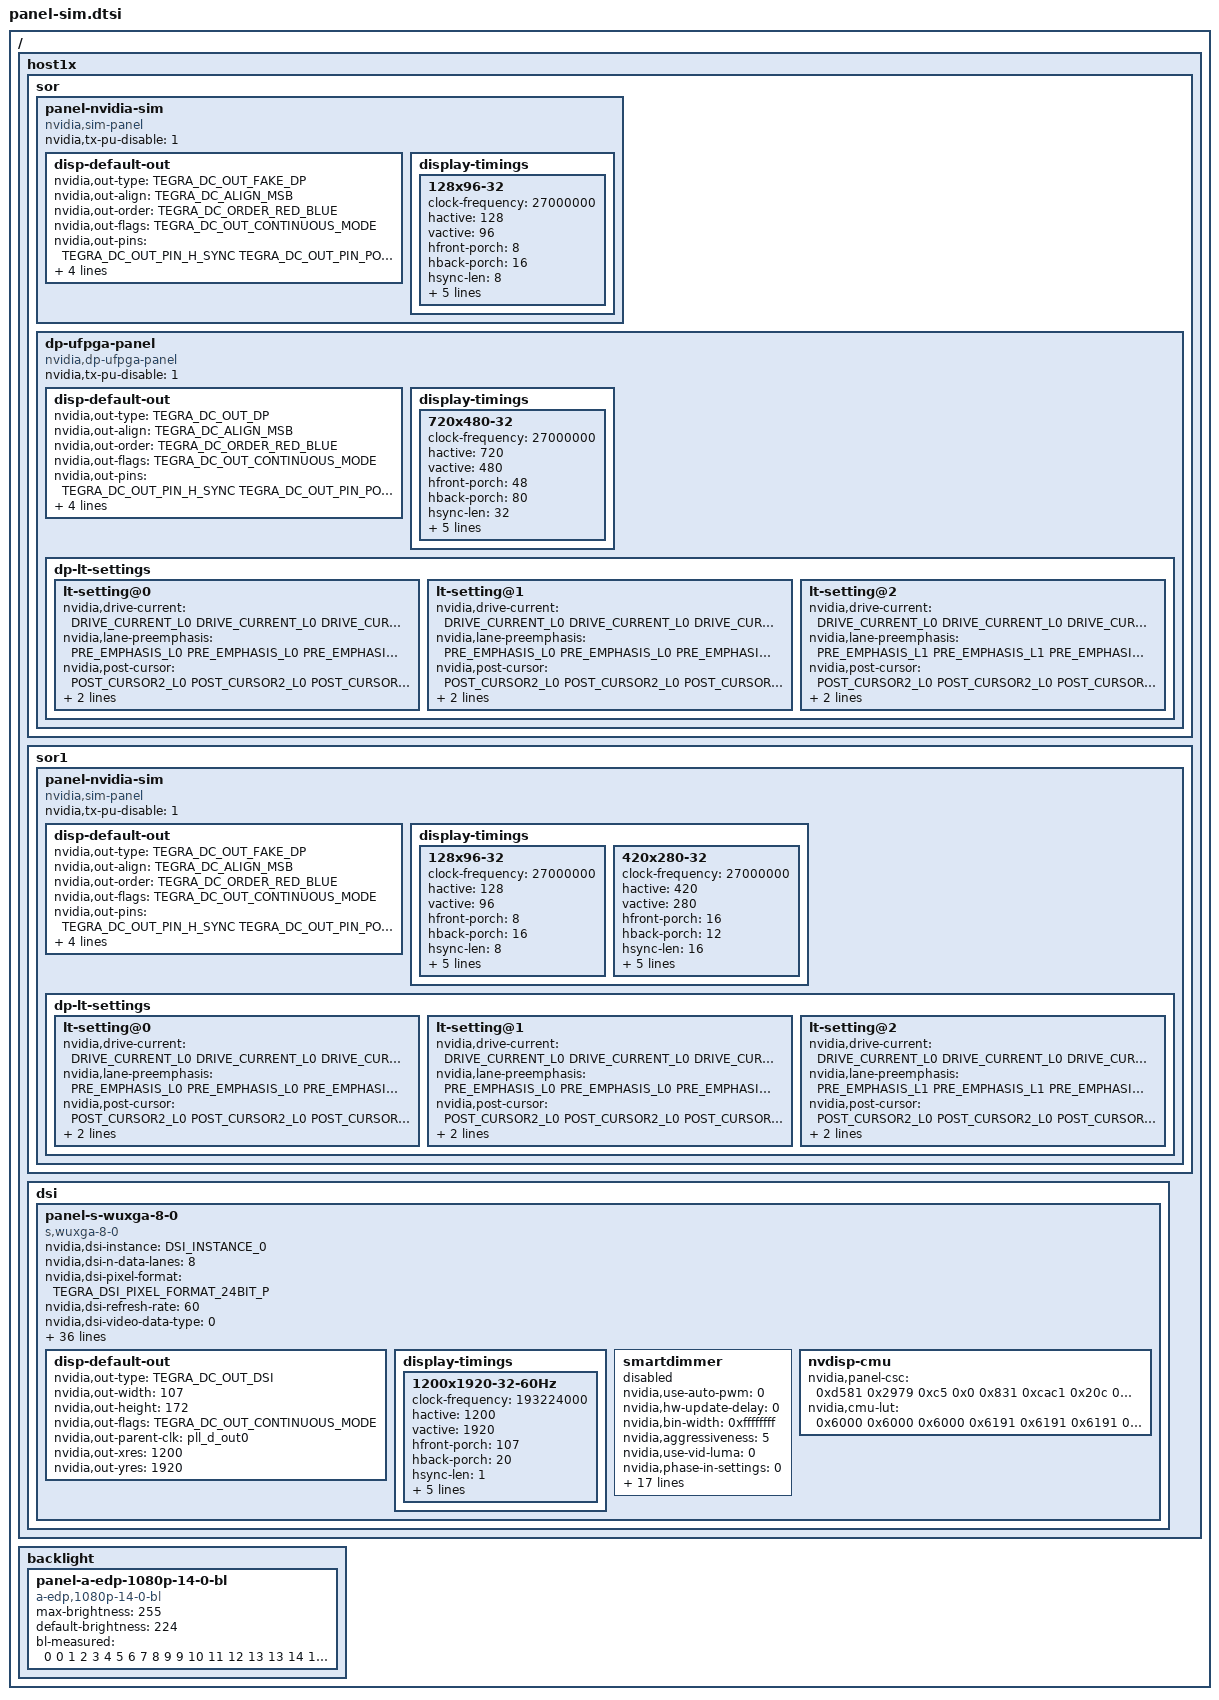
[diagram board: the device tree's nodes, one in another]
/*
 * arch/arm/boot/dts/panel-sim.dtsi
 *
 * Copyright (c) 2014-2016, NVIDIA CORPORATION.  All rights reserved.
 *
 * This program is free software; you can redistribute it and/or modify
 * it under the terms of the GNU General Public License as published by
 * the Free Software Foundation; either version 2 of the License, or
 * (at your option) any later version.
 *
 * This program is distributed in the hope that it will be useful, but WITHOUT
 * ANY WARRANTY; without even the implied warranty of MERCHANTABILITY or
 * FITNESS FOR A PARTICULAR PURPOSE.  See the GNU General Public License for
 * more details.
 *
 * You should have received a copy of the GNU General Public License along
 * with this program; if not, write to the Free Software Foundation, Inc.,
 * 51 Franklin Street, Fifth Floor, Boston, MA  02110-1301, USA.
 */
#include <dt-bindings/display/tegra-dc.h>
#include <dt-bindings/display/tegra-panel.h>

/ {
	host1x {
		sor {
			panel-nvidia-sim {
				compatible = "nvidia,sim-panel";
				nvidia,tx-pu-disable = <1>;
				disp-default-out {
					nvidia,out-type = <TEGRA_DC_OUT_FAKE_DP>;
					nvidia,out-align = <TEGRA_DC_ALIGN_MSB>;
					nvidia,out-order = <TEGRA_DC_ORDER_RED_BLUE>;
					nvidia,out-flags = <TEGRA_DC_OUT_CONTINUOUS_MODE>;
					nvidia,out-pins = <TEGRA_DC_OUT_PIN_H_SYNC TEGRA_DC_OUT_PIN_POL_LOW
							   TEGRA_DC_OUT_PIN_V_SYNC TEGRA_DC_OUT_PIN_POL_LOW
							   TEGRA_DC_OUT_PIN_PIXEL_CLOCK TEGRA_DC_OUT_PIN_POL_LOW
							   TEGRA_DC_OUT_PIN_DATA_ENABLE TEGRA_DC_OUT_PIN_POL_HIGH>;
					nvidia,out-depth = <18>;
					nvidia,out-parent-clk = "pll_d_out0";
					nvidia,out-xres = <128>;
					nvidia,out-yres = <96>;
				};
				display-timings {
					128x96-32 {
						clock-frequency = <27000000>;
						hactive = <128>;
						vactive = <96>;
						hfront-porch = <8>;
						hback-porch = <16>;
						hsync-len = <8>;
						vfront-porch = <3>;
						vback-porch = <3>;
						vsync-len = <4>;
						nvidia,h-ref-to-sync = <1>;
						nvidia,v-ref-to-sync = <1>;
					};
				};
			};

			dp-ufpga-panel {
				compatible = "nvidia,dp-ufpga-panel";
				nvidia,tx-pu-disable = <1>;
				disp-default-out {
					nvidia,out-type = <TEGRA_DC_OUT_DP>;
					nvidia,out-align = <TEGRA_DC_ALIGN_MSB>;
					nvidia,out-order = <TEGRA_DC_ORDER_RED_BLUE>;
					nvidia,out-flags = <TEGRA_DC_OUT_CONTINUOUS_MODE>;
					nvidia,out-pins = <TEGRA_DC_OUT_PIN_H_SYNC TEGRA_DC_OUT_PIN_POL_LOW
							   TEGRA_DC_OUT_PIN_V_SYNC TEGRA_DC_OUT_PIN_POL_LOW
							   TEGRA_DC_OUT_PIN_PIXEL_CLOCK TEGRA_DC_OUT_PIN_POL_LOW
							   TEGRA_DC_OUT_PIN_DATA_ENABLE TEGRA_DC_OUT_PIN_POL_HIGH>;
					nvidia,out-depth = <18>;
					nvidia,out-parent-clk = "pll_d_out0";
					nvidia,out-xres = <720>;
					nvidia,out-yres = <480>;
				};
				display-timings {
					720x480-32 {
						clock-frequency = <27000000>;
						hactive = <720>;
						vactive = <480>;
						hfront-porch = <48>;
						hback-porch = <80>;
						hsync-len = <32>;
						vfront-porch = <24>;
						vback-porch = <126>;
						vsync-len = <10>;
						nvidia,h-ref-to-sync = <1>;
						nvidia,v-ref-to-sync = <1>;
					};
				};
				dp-lt-settings {
					lt-setting@0 {
						nvidia,drive-current = <DRIVE_CURRENT_L0 DRIVE_CURRENT_L0 DRIVE_CURRENT_L0 DRIVE_CURRENT_L0>;
						nvidia,lane-preemphasis = <PRE_EMPHASIS_L0 PRE_EMPHASIS_L0 PRE_EMPHASIS_L0 PRE_EMPHASIS_L0>;
						nvidia,post-cursor = <POST_CURSOR2_L0 POST_CURSOR2_L0 POST_CURSOR2_L0 POST_CURSOR2_L0>;
						nvidia,tx-pu = <0>;
						nvidia,load-adj = <0x3>;
					};
					lt-setting@1 {
						nvidia,drive-current = <DRIVE_CURRENT_L0 DRIVE_CURRENT_L0 DRIVE_CURRENT_L0 DRIVE_CURRENT_L0>;
						nvidia,lane-preemphasis = <PRE_EMPHASIS_L0 PRE_EMPHASIS_L0 PRE_EMPHASIS_L0 PRE_EMPHASIS_L0>;
						nvidia,post-cursor = <POST_CURSOR2_L0 POST_CURSOR2_L0 POST_CURSOR2_L0 POST_CURSOR2_L0>;
						nvidia,tx-pu = <0>;
						nvidia,load-adj = <0x4>;
					};
					lt-setting@2 {
						nvidia,drive-current = <DRIVE_CURRENT_L0 DRIVE_CURRENT_L0 DRIVE_CURRENT_L0 DRIVE_CURRENT_L0>;
						nvidia,lane-preemphasis = <PRE_EMPHASIS_L1 PRE_EMPHASIS_L1 PRE_EMPHASIS_L1 PRE_EMPHASIS_L1>;
						nvidia,post-cursor = <POST_CURSOR2_L0 POST_CURSOR2_L0 POST_CURSOR2_L0 POST_CURSOR2_L0>;
						nvidia,tx-pu = <0>;
						nvidia,load-adj = <0x6>;
					};
				};
			};
		};

		sor1 {
			panel-nvidia-sim {
				compatible = "nvidia,sim-panel";
				nvidia,tx-pu-disable = <1>;
				disp-default-out {
					nvidia,out-type = <TEGRA_DC_OUT_FAKE_DP>;
					nvidia,out-align = <TEGRA_DC_ALIGN_MSB>;
					nvidia,out-order = <TEGRA_DC_ORDER_RED_BLUE>;
					nvidia,out-flags = <TEGRA_DC_OUT_CONTINUOUS_MODE>;
					nvidia,out-pins = <TEGRA_DC_OUT_PIN_H_SYNC TEGRA_DC_OUT_PIN_POL_LOW
							   TEGRA_DC_OUT_PIN_V_SYNC TEGRA_DC_OUT_PIN_POL_LOW
							   TEGRA_DC_OUT_PIN_PIXEL_CLOCK TEGRA_DC_OUT_PIN_POL_LOW
							   TEGRA_DC_OUT_PIN_DATA_ENABLE TEGRA_DC_OUT_PIN_POL_HIGH>;
					nvidia,out-depth = <18>;
					nvidia,out-parent-clk = "pll_d_out0";
					nvidia,out-xres = <128>;
					nvidia,out-yres = <96>;
				};
				display-timings {
					128x96-32 {
						clock-frequency = <27000000>;
						hactive = <128>;
						vactive = <96>;
						hfront-porch = <8>;
						hback-porch = <16>;
						hsync-len = <8>;
						vfront-porch = <3>;
						vback-porch = <3>;
						vsync-len = <4>;
						nvidia,h-ref-to-sync = <1>;
						nvidia,v-ref-to-sync = <1>;
					};
					420x280-32 {
						clock-frequency = <27000000>;
						hactive = <420>;
						vactive = <280>;
						hfront-porch = <16>;
						hback-porch = <12>;
						hsync-len = <16>;
						vfront-porch = <3>;
						vback-porch = <19>;
						vsync-len = <14>;
						nvidia,h-ref-to-sync = <11>;
						nvidia,v-ref-to-sync = <1>;
					};
				};
				dp-lt-settings {
					lt-setting@0 {
						nvidia,drive-current = <DRIVE_CURRENT_L0 DRIVE_CURRENT_L0 DRIVE_CURRENT_L0 DRIVE_CURRENT_L0>;
						nvidia,lane-preemphasis = <PRE_EMPHASIS_L0 PRE_EMPHASIS_L0 PRE_EMPHASIS_L0 PRE_EMPHASIS_L0>;
						nvidia,post-cursor = <POST_CURSOR2_L0 POST_CURSOR2_L0 POST_CURSOR2_L0 POST_CURSOR2_L0>;
						nvidia,tx-pu = <0>;
						nvidia,load-adj = <0x3>;
					};
					lt-setting@1 {
						nvidia,drive-current = <DRIVE_CURRENT_L0 DRIVE_CURRENT_L0 DRIVE_CURRENT_L0 DRIVE_CURRENT_L0>;
						nvidia,lane-preemphasis = <PRE_EMPHASIS_L0 PRE_EMPHASIS_L0 PRE_EMPHASIS_L0 PRE_EMPHASIS_L0>;
						nvidia,post-cursor = <POST_CURSOR2_L0 POST_CURSOR2_L0 POST_CURSOR2_L0 POST_CURSOR2_L0>;
						nvidia,tx-pu = <0>;
						nvidia,load-adj = <0x4>;
					};
					lt-setting@2 {
						nvidia,drive-current = <DRIVE_CURRENT_L0 DRIVE_CURRENT_L0 DRIVE_CURRENT_L0 DRIVE_CURRENT_L0>;
						nvidia,lane-preemphasis = <PRE_EMPHASIS_L1 PRE_EMPHASIS_L1 PRE_EMPHASIS_L1 PRE_EMPHASIS_L1>;
						nvidia,post-cursor = <POST_CURSOR2_L0 POST_CURSOR2_L0 POST_CURSOR2_L0 POST_CURSOR2_L0>;
						nvidia,tx-pu = <0>;
						nvidia,load-adj = <0x6>;
					};
				};
			};
		};
		dsi {
			panel-s-wuxga-8-0 {
				status = "okay";
				compatible = "s,wuxga-8-0";
				nvidia,dsi-instance = <DSI_INSTANCE_0>;
				nvidia,dsi-n-data-lanes = <8>;
				nvidia,dsi-pixel-format = <TEGRA_DSI_PIXEL_FORMAT_24BIT_P>;
				nvidia,dsi-refresh-rate = <60>;
				nvidia,dsi-video-data-type = <0>;
				nvidia,dsi-video-clock-mode = <0>;
				nvidia,dsi-video-burst-mode = <0>;
				nvidia,dsi-ganged-type = <TEGRA_DSI_GANGED_SYMMETRIC_LEFT_RIGHT>;
				nvidia,dsi-ganged-swap-links = <1>;
				nvidia,dsi-ganged-write-to-all-links = <1>;
				nvidia,dsi-controller-vs = <DSI_VS_1>;
				nvidia,dsi-virtual-channel = <TEGRA_DSI_VIRTUAL_CHANNEL_0>;
				nvidia,dsi-panel-reset = <TEGRA_DSI_ENABLE>;
				nvidia,dsi-power-saving-suspend = <TEGRA_DSI_ENABLE>;
				nvidia,dsi-ulpm-not-support = <TEGRA_DSI_ENABLE>;
				nvidia,dsi-suspend-stop-stream-late = <1>;
				nvidia,dsi-init-cmd =
					/* Long  Packet: <PACKETTYPE[u8] COMMANDID[u8] PAYLOADCOUNT[u16] ECC[u8] PAYLOAD[..] CHECKSUM[u16]> */
					/* Short Packet: <PACKETTYPE[u8] COMMANDID[u8] DATA0[u8] DATA1[u8] ECC[u8]> */
					/* For DSI packets each DT cell is interpreted as u8 not u32 */

					<TEGRA_DSI_PACKET_CMD DSI_DCS_WRITE_0_PARAM DSI_DCS_EXIT_SLEEP_MODE 0x0 0x0>,
					/* This panel has a very sensitive power on/off sequence.
					 * Send a few more frames for safety. No max limit from vendor. */
					<TEGRA_DSI_SEND_FRAME 10>,
					<TEGRA_DSI_PACKET_CMD DSI_DCS_WRITE_0_PARAM DSI_DCS_SET_DISPLAY_ON 0x0 0x0>;
				nvidia,dsi-n-init-cmd = <3>;
				nvidia,dsi-suspend-cmd =
					<TEGRA_DSI_PACKET_CMD DSI_DCS_WRITE_0_PARAM DSI_DCS_SET_DISPLAY_OFF 0x0 0x0>,
					<TEGRA_DSI_SEND_FRAME 3>,
					<TEGRA_DSI_PACKET_CMD DSI_DCS_WRITE_0_PARAM DSI_DCS_ENTER_SLEEP_MODE 0x0 0x0>,
					<TEGRA_DSI_SEND_FRAME 10>;
				nvidia,dsi-n-suspend-cmd = <4>;
				nvidia,dsi-pkt-seq =
					<CMD_VS LEN_SHORT PKT_LP LINE_STOP>,
					<CMD_HS LEN_SHORT PKT_LP LINE_STOP>,
					<CMD_HS LEN_SHORT PKT_LP LINE_STOP>,
					<CMD_HS LEN_SHORT CMD_RGB_24BPP LEN_HACTIVE3 CMD_BLNK LEN_HFP LINE_STOP>,
					<CMD_HS LEN_SHORT PKT_LP LINE_STOP>,
					<CMD_HS LEN_SHORT CMD_RGB_24BPP LEN_HACTIVE3 CMD_BLNK LEN_HFP LINE_STOP>;
				nvdia,panel-rst-gpio = <0x11 0x7b 0x1>;
				nvidia,panel-bl-pwm-gpio = <0x11 0xa0 0x1>;
				nvidia,panel-bl-en-gpio = <0x11 0xa3 0x1>;
				nvidia,en-vmm-vpp-with-i2c-config;
				disp-default-out {
					nvidia,out-type = <TEGRA_DC_OUT_DSI>;
					nvidia,out-width = <107>;
					nvidia,out-height = <172>;
					nvidia,out-flags = <TEGRA_DC_OUT_CONTINUOUS_MODE>;
					nvidia,out-parent-clk = "pll_d_out0";
					nvidia,out-xres = <1200>;
					nvidia,out-yres = <1920>;
				};
				display-timings {
					1200x1920-32-60Hz {
						clock-frequency = <193224000>;
						hactive = <1200>;
						vactive = <1920>;
						hfront-porch = <107>;
						hback-porch = <20>;
						hsync-len = <1>;
						vfront-porch = <497>;
						vback-porch = <7>;
						vsync-len = <1>;
						nvidia,h-ref-to-sync = <1>;
						nvidia,v-ref-to-sync = <11>;
					};
				};
				smartdimmer {
					status = "disabled";
					nvidia,use-auto-pwm = <0>;
					nvidia,hw-update-delay = <0>;
					nvidia,bin-width = <0xffffffff>;
					nvidia,aggressiveness = <5>;
					nvidia,use-vid-luma = <0>;
					nvidia,phase-in-settings = <0>;
					nvidia,phase-in-adjustments = <0>;
					nvidia,k-limit-enable = <1>;
					nvidia,k-limit = <200>;
					nvidia,sd-window-enable = <0>;
					nvidia,soft-clipping-enable= <1>;
					nvidia,soft-clipping-threshold = <128>;
					nvidia,smooth-k-enable = <1>;
					nvidia,smooth-k-incr = <4>;
					nvidia,coeff = <5 9 2>;
					nvidia,fc = <0 0>;
					nvidia,blp = <1024 255>;
					nvidia,bltf = <57 65 73 82
						       92 103 114 125
						       138 150 164 178
						       193 208 224 241>;
					nvidia,lut = <255 255 255
					              199 199 199
						      153 153 153
						      116 116 116
						      85 85 85
						      59 59 59
						      36 36 36
						      17 17 17
						      0 0 0>;
					nvidia,use-vpulse2 = <1>;
					nvidia,bl-device-name = "pwm-backlight";
				};
				nvdisp-cmu {
					nvidia,panel-csc = <0xd581 0x2979 0xc5 0x0 0x831 0xcac1 0x20c 0x0 0x189 0x625 0xcc4a 0x0>;
					nvidia,cmu-lut = <0x6000 0x6000 0x6000 0x6191 0x6191 0x6191 0x6322 0x6322 0x6322
							  0x643b 0x643b 0x643b 0x64ba 0x64ba 0x64ba 0x6539 0x6539 0x6539
							  0x65b8 0x65b8 0x65b8 0x6637 0x6637 0x6637 0x66b6 0x66b6 0x66b6
							  0x6735 0x6735 0x6735 0x67b4 0x67b4 0x67b4 0x6826 0x6826 0x6826
							  0x687d 0x687d 0x687d 0x68d4 0x68d4 0x68d4 0x692b 0x692b 0x692b
							  0x6983 0x6983 0x6983 0x69da 0x69da 0x69da 0x6a31 0x6a31 0x6a31
							  0x6a88 0x6a88 0x6a88 0x6ae0 0x6ae0 0x6ae0 0x6b37 0x6b37 0x6b37
							  0x6b8e 0x6b8e 0x6b8e 0x6be5 0x6be5 0x6be5 0x6c28 0x6c28 0x6c28
							  0x6c5b 0x6c5b 0x6c5b 0x6c8e 0x6c8e 0x6c8e 0x6cc1 0x6cc1 0x6cc1
							  0x6cf4 0x6cf4 0x6cf4 0x6d27 0x6d27 0x6d27 0x6d5a 0x6d5a 0x6d5a
							  0x6d8d 0x6d8d 0x6d8d 0x6dbf 0x6dbf 0x6dbf 0x6df2 0x6df2 0x6df2
							  0x6e25 0x6e25 0x6e25 0x6e58 0x6e58 0x6e58 0x6e8b 0x6e8b 0x6e8b
							  0x6ebe 0x6ebe 0x6ebe 0x6ef1 0x6ef1 0x6ef1 0x6f24 0x6f24 0x6f24
							  0x6f57 0x6f57 0x6f57 0x6f8a 0x6f8a 0x6f8a 0x6fbd 0x6fbd 0x6fbd
							  0x6ff0 0x6ff0 0x6ff0 0x701a 0x701a 0x701a 0x7037 0x7037 0x7037
							  0x7053 0x7053 0x7053 0x706f 0x706f 0x706f 0x708c 0x708c 0x708c
							  0x70a8 0x70a8 0x70a8 0x70c5 0x70c5 0x70c5 0x70e1 0x70e1 0x70e1
							  0x70fe 0x70fe 0x70fe 0x711a 0x711a 0x711a 0x7136 0x7136 0x7136
							  0x7153 0x7153 0x7153 0x716f 0x716f 0x716f 0x718c 0x718c 0x718c
							  0x71a8 0x71a8 0x71a8 0x71c4 0x71c4 0x71c4 0x71e1 0x71e1 0x71e1
							  0x71fd 0x71fd 0x71fd 0x721a 0x721a 0x721a 0x7236 0x7236 0x7236
							  0x7253 0x7253 0x7253 0x726f 0x726f 0x726f 0x728b 0x728b 0x728b
							  0x72a8 0x72a8 0x72a8 0x72c4 0x72c4 0x72c4 0x72e1 0x72e1 0x72e1
							  0x72fd 0x72fd 0x72fd 0x731a 0x731a 0x731a 0x7336 0x7336 0x7336
							  0x7352 0x7352 0x7352 0x736f 0x736f 0x736f 0x738b 0x738b 0x738b
							  0x73a8 0x73a8 0x73a8 0x73c4 0x73c4 0x73c4 0x73e1 0x73e1 0x73e1
							  0x73fd 0x73fd 0x73fd 0x741b 0x741b 0x741b 0x743f 0x743f 0x743f
							  0x7463 0x7463 0x7463 0x7486 0x7486 0x7486 0x74aa 0x74aa 0x74aa
							  0x74ce 0x74ce 0x74ce 0x74f2 0x74f2 0x74f2 0x7516 0x7516 0x7516
							  0x753a 0x753a 0x753a 0x755d 0x755d 0x755d 0x7581 0x7581 0x7581
							  0x75a5 0x75a5 0x75a5 0x75c9 0x75c9 0x75c9 0x75ed 0x75ed 0x75ed
							  0x7611 0x7611 0x7611 0x7634 0x7634 0x7634 0x7658 0x7658 0x7658
							  0x767c 0x767c 0x767c 0x76a0 0x76a0 0x76a0 0x76c4 0x76c4 0x76c4
							  0x76e8 0x76e8 0x76e8 0x770b 0x770b 0x770b 0x772f 0x772f 0x772f
							  0x7753 0x7753 0x7753 0x7777 0x7777 0x7777 0x779b 0x779b 0x779b
							  0x77bf 0x77bf 0x77bf 0x77e2 0x77e2 0x77e2 0x7806 0x7806 0x7806
							  0x7825 0x7825 0x7825 0x7840 0x7840 0x7840 0x785b 0x785b 0x785b
							  0x7876 0x7876 0x7876 0x7891 0x7891 0x7891 0x78ac 0x78ac 0x78ac
							  0x78c7 0x78c7 0x78c7 0x78e2 0x78e2 0x78e2 0x78fd 0x78fd 0x78fd
							  0x7918 0x7918 0x7918 0x7933 0x7933 0x7933 0x794e 0x794e 0x794e
							  0x7969 0x7969 0x7969 0x7984 0x7984 0x7984 0x799f 0x799f 0x799f
							  0x79ba 0x79ba 0x79ba 0x79d5 0x79d5 0x79d5 0x79f0 0x79f0 0x79f0
							  0x7a0b 0x7a0b 0x7a0b 0x7a26 0x7a26 0x7a26 0x7a41 0x7a41 0x7a41
							  0x7a5c 0x7a5c 0x7a5c 0x7a77 0x7a77 0x7a77 0x7a92 0x7a92 0x7a92
							  0x7aad 0x7aad 0x7aad 0x7ac8 0x7ac8 0x7ac8 0x7ae3 0x7ae3 0x7ae3
							  0x7afe 0x7afe 0x7afe 0x7b19 0x7b19 0x7b19 0x7b34 0x7b34 0x7b34
							  0x7b4f 0x7b4f 0x7b4f 0x7b6a 0x7b6a 0x7b6a 0x7b85 0x7b85 0x7b85
							  0x7ba0 0x7ba0 0x7ba0 0x7bbb 0x7bbb 0x7bbb 0x7bd5 0x7bd5 0x7bd5
							  0x7bf0 0x7bf0 0x7bf0 0x7c0b 0x7c0b 0x7c0b 0x7c23 0x7c23 0x7c23
							  0x7c35 0x7c35 0x7c35 0x7c47 0x7c47 0x7c47 0x7c59 0x7c59 0x7c59
							  0x7c6b 0x7c6b 0x7c6b 0x7c7d 0x7c7d 0x7c7d 0x7c90 0x7c90 0x7c90
							  0x7ca2 0x7ca2 0x7ca2 0x7cb4 0x7cb4 0x7cb4 0x7cc6 0x7cc6 0x7cc6
							  0x7cd8 0x7cd8 0x7cd8 0x7cea 0x7cea 0x7cea 0x7cfc 0x7cfc 0x7cfc
							  0x7d0f 0x7d0f 0x7d0f 0x7d21 0x7d21 0x7d21 0x7d33 0x7d33 0x7d33
							  0x7d45 0x7d45 0x7d45 0x7d57 0x7d57 0x7d57 0x7d69 0x7d69 0x7d69
							  0x7d7b 0x7d7b 0x7d7b 0x7d8e 0x7d8e 0x7d8e 0x7da0 0x7da0 0x7da0
							  0x7db2 0x7db2 0x7db2 0x7dc4 0x7dc4 0x7dc4 0x7dd6 0x7dd6 0x7dd6
							  0x7de8 0x7de8 0x7de8 0x7dfa 0x7dfa 0x7dfa 0x7e0d 0x7e0d 0x7e0d
							  0x7e1f 0x7e1f 0x7e1f 0x7e31 0x7e31 0x7e31 0x7e43 0x7e43 0x7e43
							  0x7e55 0x7e55 0x7e55 0x7e67 0x7e67 0x7e67 0x7e79 0x7e79 0x7e79
							  0x7e8c 0x7e8c 0x7e8c 0x7e9e 0x7e9e 0x7e9e 0x7eb0 0x7eb0 0x7eb0
							  0x7ec2 0x7ec2 0x7ec2 0x7ed4 0x7ed4 0x7ed4 0x7ee6 0x7ee6 0x7ee6
							  0x7ef8 0x7ef8 0x7ef8 0x7f0b 0x7f0b 0x7f0b 0x7f1d 0x7f1d 0x7f1d
							  0x7f2f 0x7f2f 0x7f2f 0x7f41 0x7f41 0x7f41 0x7f53 0x7f53 0x7f53
							  0x7f65 0x7f65 0x7f65 0x7f77 0x7f77 0x7f77 0x7f8a 0x7f8a 0x7f8a
							  0x7f9c 0x7f9c 0x7f9c 0x7fae 0x7fae 0x7fae 0x7fc0 0x7fc0 0x7fc0
							  0x7fd2 0x7fd2 0x7fd2 0x7fe4 0x7fe4 0x7fe4 0x7ff7 0x7ff7 0x7ff7
							  0x8009 0x8009 0x8009 0x801b 0x801b 0x801b 0x802b 0x802b 0x802b
							  0x803a 0x803a 0x803a 0x804a 0x804a 0x804a 0x8059 0x8059 0x8059
							  0x8069 0x8069 0x8069 0x8078 0x8078 0x8078 0x8087 0x8087 0x8087
							  0x8097 0x8097 0x8097 0x80a6 0x80a6 0x80a6 0x80b6 0x80b6 0x80b6
							  0x80c5 0x80c5 0x80c5 0x80d5 0x80d5 0x80d5 0x80e4 0x80e4 0x80e4
							  0x80f4 0x80f4 0x80f4 0x8103 0x8103 0x8103 0x8112 0x8112 0x8112
							  0x8122 0x8122 0x8122 0x8131 0x8131 0x8131 0x8141 0x8141 0x8141
							  0x8150 0x8150 0x8150 0x8160 0x8160 0x8160 0x816f 0x816f 0x816f
							  0x817e 0x817e 0x817e 0x818e 0x818e 0x818e 0x819d 0x819d 0x819d
							  0x81ad 0x81ad 0x81ad 0x81bc 0x81bc 0x81bc 0x81cc 0x81cc 0x81cc
							  0x81db 0x81db 0x81db 0x81eb 0x81eb 0x81eb 0x81fa 0x81fa 0x81fa
							  0x8209 0x8209 0x8209 0x8219 0x8219 0x8219 0x8228 0x8228 0x8228
							  0x8238 0x8238 0x8238 0x8247 0x8247 0x8247 0x8257 0x8257 0x8257
							  0x8266 0x8266 0x8266 0x8275 0x8275 0x8275 0x8285 0x8285 0x8285
							  0x8294 0x8294 0x8294 0x82a4 0x82a4 0x82a4 0x82b3 0x82b3 0x82b3
							  0x82c3 0x82c3 0x82c3 0x82d2 0x82d2 0x82d2 0x82e2 0x82e2 0x82e2
							  0x82f1 0x82f1 0x82f1 0x8300 0x8300 0x8300 0x8310 0x8310 0x8310
							  0x831f 0x831f 0x831f 0x832f 0x832f 0x832f 0x833e 0x833e 0x833e
							  0x834e 0x834e 0x834e 0x835d 0x835d 0x835d 0x836c 0x836c 0x836c
							  0x837c 0x837c 0x837c 0x838b 0x838b 0x838b 0x839b 0x839b 0x839b
							  0x83aa 0x83aa 0x83aa 0x83ba 0x83ba 0x83ba 0x83c9 0x83c9 0x83c9
							  0x83d8 0x83d8 0x83d8 0x83e8 0x83e8 0x83e8 0x83f7 0x83f7 0x83f7
							  0x8407 0x8407 0x8407 0x8416 0x8416 0x8416 0x8425 0x8425 0x8425
							  0x8431 0x8431 0x8431 0x843d 0x843d 0x843d 0x8449 0x8449 0x8449
							  0x8455 0x8455 0x8455 0x8462 0x8462 0x8462 0x846e 0x846e 0x846e
							  0x847a 0x847a 0x847a 0x8486 0x8486 0x8486 0x8492 0x8492 0x8492
							  0x849e 0x849e 0x849e 0x84aa 0x84aa 0x84aa 0x84b6 0x84b6 0x84b6
							  0x84c2 0x84c2 0x84c2 0x84ce 0x84ce 0x84ce 0x84da 0x84da 0x84da
							  0x84e7 0x84e7 0x84e7 0x84f3 0x84f3 0x84f3 0x84ff 0x84ff 0x84ff
							  0x850b 0x850b 0x850b 0x8517 0x8517 0x8517 0x8523 0x8523 0x8523
							  0x852f 0x852f 0x852f 0x853b 0x853b 0x853b 0x8547 0x8547 0x8547
							  0x8553 0x8553 0x8553 0x855f 0x855f 0x855f 0x856c 0x856c 0x856c
							  0x8578 0x8578 0x8578 0x8584 0x8584 0x8584 0x8590 0x8590 0x8590
							  0x859c 0x859c 0x859c 0x85a8 0x85a8 0x85a8 0x85b4 0x85b4 0x85b4
							  0x85c0 0x85c0 0x85c0 0x85cc 0x85cc 0x85cc 0x85d8 0x85d8 0x85d8
							  0x85e4 0x85e4 0x85e4 0x85f0 0x85f0 0x85f0 0x85fd 0x85fd 0x85fd
							  0x8609 0x8609 0x8609 0x8615 0x8615 0x8615 0x8621 0x8621 0x8621
							  0x862d 0x862d 0x862d 0x8639 0x8639 0x8639 0x8645 0x8645 0x8645
							  0x8651 0x8651 0x8651 0x865d 0x865d 0x865d 0x8669 0x8669 0x8669
							  0x8675 0x8675 0x8675 0x8682 0x8682 0x8682 0x868e 0x868e 0x868e
							  0x869a 0x869a 0x869a 0x86a6 0x86a6 0x86a6 0x86b2 0x86b2 0x86b2
							  0x86be 0x86be 0x86be 0x86ca 0x86ca 0x86ca 0x86d6 0x86d6 0x86d6
							  0x86e2 0x86e2 0x86e2 0x86ee 0x86ee 0x86ee 0x86fa 0x86fa 0x86fa
							  0x8707 0x8707 0x8707 0x8713 0x8713 0x8713 0x871f 0x871f 0x871f
							  0x872b 0x872b 0x872b 0x8737 0x8737 0x8737 0x8743 0x8743 0x8743
							  0x874f 0x874f 0x874f 0x875b 0x875b 0x875b 0x8767 0x8767 0x8767
							  0x8773 0x8773 0x8773 0x877f 0x877f 0x877f 0x878b 0x878b 0x878b
							  0x8798 0x8798 0x8798 0x87a4 0x87a4 0x87a4 0x87b0 0x87b0 0x87b0
							  0x87bc 0x87bc 0x87bc 0x87c8 0x87c8 0x87c8 0x87d4 0x87d4 0x87d4
							  0x87e0 0x87e0 0x87e0 0x87ec 0x87ec 0x87ec 0x87f8 0x87f8 0x87f8
							  0x8804 0x8804 0x8804 0x8810 0x8810 0x8810 0x881d 0x881d 0x881d
							  0x8829 0x8829 0x8829 0x8834 0x8834 0x8834 0x883f 0x883f 0x883f
							  0x884b 0x884b 0x884b 0x8856 0x8856 0x8856 0x8862 0x8862 0x8862
							  0x886d 0x886d 0x886d 0x8879 0x8879 0x8879 0x8884 0x8884 0x8884
							  0x8890 0x8890 0x8890 0x889b 0x889b 0x889b 0x88a6 0x88a6 0x88a6
							  0x88b2 0x88b2 0x88b2 0x88bd 0x88bd 0x88bd 0x88c9 0x88c9 0x88c9
							  0x88d4 0x88d4 0x88d4 0x88e0 0x88e0 0x88e0 0x88eb 0x88eb 0x88eb
							  0x88f6 0x88f6 0x88f6 0x8902 0x8902 0x8902 0x890d 0x890d 0x890d
							  0x8919 0x8919 0x8919 0x8924 0x8924 0x8924 0x8930 0x8930 0x8930
							  0x893b 0x893b 0x893b 0x8947 0x8947 0x8947 0x8952 0x8952 0x8952
							  0x895d 0x895d 0x895d 0x8969 0x8969 0x8969 0x8974 0x8974 0x8974
							  0x8980 0x8980 0x8980 0x898b 0x898b 0x898b 0x8997 0x8997 0x8997
							  0x89a2 0x89a2 0x89a2 0x89ae 0x89ae 0x89ae 0x89b9 0x89b9 0x89b9
							  0x89c4 0x89c4 0x89c4 0x89d0 0x89d0 0x89d0 0x89db 0x89db 0x89db
							  0x89e7 0x89e7 0x89e7 0x89f2 0x89f2 0x89f2 0x89fe 0x89fe 0x89fe
							  0x8a09 0x8a09 0x8a09 0x8a15 0x8a15 0x8a15 0x8a20 0x8a20 0x8a20
							  0x8a2b 0x8a2b 0x8a2b 0x8a37 0x8a37 0x8a37 0x8a42 0x8a42 0x8a42
							  0x8a4e 0x8a4e 0x8a4e 0x8a59 0x8a59 0x8a59 0x8a65 0x8a65 0x8a65
							  0x8a70 0x8a70 0x8a70 0x8a7b 0x8a7b 0x8a7b 0x8a87 0x8a87 0x8a87
							  0x8a92 0x8a92 0x8a92 0x8a9e 0x8a9e 0x8a9e 0x8aa9 0x8aa9 0x8aa9
							  0x8ab5 0x8ab5 0x8ab5 0x8ac0 0x8ac0 0x8ac0 0x8acc 0x8acc 0x8acc
							  0x8ad7 0x8ad7 0x8ad7 0x8ae2 0x8ae2 0x8ae2 0x8aee 0x8aee 0x8aee
							  0x8af9 0x8af9 0x8af9 0x8b05 0x8b05 0x8b05 0x8b10 0x8b10 0x8b10
							  0x8b1c 0x8b1c 0x8b1c 0x8b27 0x8b27 0x8b27 0x8b33 0x8b33 0x8b33
							  0x8b3e 0x8b3e 0x8b3e 0x8b49 0x8b49 0x8b49 0x8b55 0x8b55 0x8b55
							  0x8b60 0x8b60 0x8b60 0x8b6c 0x8b6c 0x8b6c 0x8b77 0x8b77 0x8b77
							  0x8b83 0x8b83 0x8b83 0x8b8e 0x8b8e 0x8b8e 0x8b99 0x8b99 0x8b99
							  0x8ba5 0x8ba5 0x8ba5 0x8bb0 0x8bb0 0x8bb0 0x8bbc 0x8bbc 0x8bbc
							  0x8bc7 0x8bc7 0x8bc7 0x8bd3 0x8bd3 0x8bd3 0x8bde 0x8bde 0x8bde
							  0x8bea 0x8bea 0x8bea 0x8bf5 0x8bf5 0x8bf5 0x8c00 0x8c00 0x8c00
							  0x8c0c 0x8c0c 0x8c0c 0x8c17 0x8c17 0x8c17 0x8c23 0x8c23 0x8c23
							  0x8c2e 0x8c2e 0x8c2e 0x8c38 0x8c38 0x8c38 0x8c43 0x8c43 0x8c43
							  0x8c4d 0x8c4d 0x8c4d 0x8c58 0x8c58 0x8c58 0x8c62 0x8c62 0x8c62
							  0x8c6c 0x8c6c 0x8c6c 0x8c77 0x8c77 0x8c77 0x8c81 0x8c81 0x8c81
							  0x8c8c 0x8c8c 0x8c8c 0x8c96 0x8c96 0x8c96 0x8ca0 0x8ca0 0x8ca0
							  0x8cab 0x8cab 0x8cab 0x8cb5 0x8cb5 0x8cb5 0x8cc0 0x8cc0 0x8cc0
							  0x8cca 0x8cca 0x8cca 0x8cd4 0x8cd4 0x8cd4 0x8cdf 0x8cdf 0x8cdf
							  0x8ce9 0x8ce9 0x8ce9 0x8cf4 0x8cf4 0x8cf4 0x8cfe 0x8cfe 0x8cfe
							  0x8d09 0x8d09 0x8d09 0x8d13 0x8d13 0x8d13 0x8d1d 0x8d1d 0x8d1d
							  0x8d28 0x8d28 0x8d28 0x8d32 0x8d32 0x8d32 0x8d3d 0x8d3d 0x8d3d
							  0x8d47 0x8d47 0x8d47 0x8d51 0x8d51 0x8d51 0x8d5c 0x8d5c 0x8d5c
							  0x8d66 0x8d66 0x8d66 0x8d71 0x8d71 0x8d71 0x8d7b 0x8d7b 0x8d7b
							  0x8d85 0x8d85 0x8d85 0x8d90 0x8d90 0x8d90 0x8d9a 0x8d9a 0x8d9a
							  0x8da5 0x8da5 0x8da5 0x8daf 0x8daf 0x8daf 0x8db9 0x8db9 0x8db9
							  0x8dc4 0x8dc4 0x8dc4 0x8dce 0x8dce 0x8dce 0x8dd9 0x8dd9 0x8dd9
							  0x8de3 0x8de3 0x8de3 0x8ded 0x8ded 0x8ded 0x8df8 0x8df8 0x8df8
							  0x8e02 0x8e02 0x8e02 0x8e0d 0x8e0d 0x8e0d 0x8e17 0x8e17 0x8e17
							  0x8e22 0x8e22 0x8e22 0x8e2c 0x8e2c 0x8e2c 0x8e36 0x8e36 0x8e36
							  0x8e41 0x8e41 0x8e41 0x8e4b 0x8e4b 0x8e4b 0x8e56 0x8e56 0x8e56
							  0x8e60 0x8e60 0x8e60 0x8e6a 0x8e6a 0x8e6a 0x8e75 0x8e75 0x8e75
							  0x8e7f 0x8e7f 0x8e7f 0x8e8a 0x8e8a 0x8e8a 0x8e94 0x8e94 0x8e94
							  0x8e9e 0x8e9e 0x8e9e 0x8ea9 0x8ea9 0x8ea9 0x8eb3 0x8eb3 0x8eb3
							  0x8ebe 0x8ebe 0x8ebe 0x8ec8 0x8ec8 0x8ec8 0x8ed2 0x8ed2 0x8ed2
							  0x8edd 0x8edd 0x8edd 0x8ee7 0x8ee7 0x8ee7 0x8ef2 0x8ef2 0x8ef2
							  0x8efc 0x8efc 0x8efc 0x8f07 0x8f07 0x8f07 0x8f11 0x8f11 0x8f11
							  0x8f1b 0x8f1b 0x8f1b 0x8f26 0x8f26 0x8f26 0x8f30 0x8f30 0x8f30
							  0x8f3b 0x8f3b 0x8f3b 0x8f45 0x8f45 0x8f45 0x8f4f 0x8f4f 0x8f4f
							  0x8f5a 0x8f5a 0x8f5a 0x8f64 0x8f64 0x8f64 0x8f6f 0x8f6f 0x8f6f
							  0x8f79 0x8f79 0x8f79 0x8f83 0x8f83 0x8f83 0x8f8e 0x8f8e 0x8f8e
							  0x8f98 0x8f98 0x8f98 0x8fa3 0x8fa3 0x8fa3 0x8fad 0x8fad 0x8fad
							  0x8fb7 0x8fb7 0x8fb7 0x8fc2 0x8fc2 0x8fc2 0x8fcc 0x8fcc 0x8fcc
							  0x8fd7 0x8fd7 0x8fd7 0x8fe1 0x8fe1 0x8fe1 0x8feb 0x8feb 0x8feb
							  0x8ff6 0x8ff6 0x8ff6 0x9000 0x9000 0x9000 0x900b 0x900b 0x900b
							  0x9015 0x9015 0x9015 0x9020 0x9020 0x9020 0x902a 0x902a 0x902a
							  0x9034 0x9034 0x9034 0x903e 0x903e 0x903e 0x9048 0x9048 0x9048
							  0x9052 0x9052 0x9052 0x905c 0x905c 0x905c 0x9066 0x9066 0x9066
							  0x9070 0x9070 0x9070 0x907a 0x907a 0x907a 0x9084 0x9084 0x9084
							  0x908e 0x908e 0x908e 0x9098 0x9098 0x9098 0x90a2 0x90a2 0x90a2
							  0x90ac 0x90ac 0x90ac 0x90b6 0x90b6 0x90b6 0x90c0 0x90c0 0x90c0
							  0x90ca 0x90ca 0x90ca 0x90d4 0x90d4 0x90d4 0x90de 0x90de 0x90de
							  0x90e8 0x90e8 0x90e8 0x90f2 0x90f2 0x90f2 0x90fc 0x90fc 0x90fc
							  0x9106 0x9106 0x9106 0x9110 0x9110 0x9110 0x911a 0x911a 0x911a
							  0x9123 0x9123 0x9123 0x912d 0x912d 0x912d 0x9137 0x9137 0x9137
							  0x9141 0x9141 0x9141 0x914b 0x914b 0x914b 0x9155 0x9155 0x9155
							  0x915f 0x915f 0x915f 0x9169 0x9169 0x9169 0x9173 0x9173 0x9173
							  0x917d 0x917d 0x917d 0x9187 0x9187 0x9187 0x9191 0x9191 0x9191
							  0x919b 0x919b 0x919b 0x91a5 0x91a5 0x91a5 0x91af 0x91af 0x91af
							  0x91b9 0x91b9 0x91b9 0x91c3 0x91c3 0x91c3 0x91cd 0x91cd 0x91cd
							  0x91d7 0x91d7 0x91d7 0x91e1 0x91e1 0x91e1 0x91eb 0x91eb 0x91eb
							  0x91f5 0x91f5 0x91f5 0x91ff 0x91ff 0x91ff 0x9209 0x9209 0x9209
							  0x9213 0x9213 0x9213 0x921d 0x921d 0x921d 0x9227 0x9227 0x9227
							  0x9231 0x9231 0x9231 0x923b 0x923b 0x923b 0x9245 0x9245 0x9245
							  0x924f 0x924f 0x924f 0x9259 0x9259 0x9259 0x9263 0x9263 0x9263
							  0x926d 0x926d 0x926d 0x9277 0x9277 0x9277 0x9281 0x9281 0x9281
							  0x928b 0x928b 0x928b 0x9295 0x9295 0x9295 0x929f 0x929f 0x929f
							  0x92a8 0x92a8 0x92a8 0x92b2 0x92b2 0x92b2 0x92bc 0x92bc 0x92bc
							  0x92c6 0x92c6 0x92c6 0x92d0 0x92d0 0x92d0 0x92da 0x92da 0x92da
							  0x92e4 0x92e4 0x92e4 0x92ee 0x92ee 0x92ee 0x92f8 0x92f8 0x92f8
							  0x9302 0x9302 0x9302 0x930c 0x930c 0x930c 0x9316 0x9316 0x9316
							  0x9320 0x9320 0x9320 0x932a 0x932a 0x932a 0x9334 0x9334 0x9334
							  0x933e 0x933e 0x933e 0x9348 0x9348 0x9348 0x9352 0x9352 0x9352
							  0x935c 0x935c 0x935c 0x9366 0x9366 0x9366 0x9370 0x9370 0x9370
							  0x937a 0x937a 0x937a 0x9384 0x9384 0x9384 0x938e 0x938e 0x938e
							  0x9398 0x9398 0x9398 0x93a2 0x93a2 0x93a2 0x93ac 0x93ac 0x93ac
							  0x93b6 0x93b6 0x93b6 0x93c0 0x93c0 0x93c0 0x93ca 0x93ca 0x93ca
							  0x93d4 0x93d4 0x93d4 0x93de 0x93de 0x93de 0x93e8 0x93e8 0x93e8
							  0x93f2 0x93f2 0x93f2 0x93fc 0x93fc 0x93fc 0x9406 0x9406 0x9406
							  0x9410 0x9410 0x9410 0x941a 0x941a 0x941a 0x9423 0x9423 0x9423
							  0x942d 0x942d 0x942d 0x9437 0x9437 0x9437 0x9440 0x9440 0x9440
							  0x9449 0x9449 0x9449 0x9451 0x9451 0x9451 0x945a 0x945a 0x945a
							  0x9463 0x9463 0x9463 0x946c 0x946c 0x946c 0x9475 0x9475 0x9475
							  0x947e 0x947e 0x947e 0x9486 0x9486 0x9486 0x948f 0x948f 0x948f
							  0x9498 0x9498 0x9498 0x94a1 0x94a1 0x94a1 0x94aa 0x94aa 0x94aa
							  0x94b3 0x94b3 0x94b3 0x94bb 0x94bb 0x94bb 0x94c4 0x94c4 0x94c4
							  0x94cd 0x94cd 0x94cd 0x94d6 0x94d6 0x94d6 0x94df 0x94df 0x94df
							  0x94e8 0x94e8 0x94e8 0x94f0 0x94f0 0x94f0 0x94f9 0x94f9 0x94f9
							  0x9502 0x9502 0x9502 0x950b 0x950b 0x950b 0x9514 0x9514 0x9514
							  0x951d 0x951d 0x951d 0x9525 0x9525 0x9525 0x952e 0x952e 0x952e
							  0x9537 0x9537 0x9537 0x9540 0x9540 0x9540 0x9549 0x9549 0x9549
							  0x9552 0x9552 0x9552 0x955a 0x955a 0x955a 0x9563 0x9563 0x9563
							  0x956c 0x956c 0x956c 0x9575 0x9575 0x9575 0x957e 0x957e 0x957e
							  0x9587 0x9587 0x9587 0x958f 0x958f 0x958f 0x9598 0x9598 0x9598
							  0x95a1 0x95a1 0x95a1 0x95aa 0x95aa 0x95aa 0x95b3 0x95b3 0x95b3
							  0x95bc 0x95bc 0x95bc 0x95c4 0x95c4 0x95c4 0x95cd 0x95cd 0x95cd
							  0x95d6 0x95d6 0x95d6 0x95df 0x95df 0x95df 0x95e8 0x95e8 0x95e8
							  0x95f1 0x95f1 0x95f1 0x95f9 0x95f9 0x95f9 0x9602 0x9602 0x9602
							  0x960b 0x960b 0x960b 0x9614 0x9614 0x9614 0x961d 0x961d 0x961d
							  0x9626 0x9626 0x9626 0x962e 0x962e 0x962e 0x9637 0x9637 0x9637
							  0x9640 0x9640 0x9640 0x9649 0x9649 0x9649 0x9652 0x9652 0x9652
							  0x965b 0x965b 0x965b 0x9663 0x9663 0x9663 0x966c 0x966c 0x966c
							  0x9675 0x9675 0x9675 0x967e 0x967e 0x967e 0x9687 0x9687 0x9687
							  0x9690 0x9690 0x9690 0x9698 0x9698 0x9698 0x96a1 0x96a1 0x96a1
							  0x96aa 0x96aa 0x96aa 0x96b3 0x96b3 0x96b3 0x96bc 0x96bc 0x96bc
							  0x96c5 0x96c5 0x96c5 0x96cd 0x96cd 0x96cd 0x96d6 0x96d6 0x96d6
							  0x96df 0x96df 0x96df 0x96e8 0x96e8 0x96e8 0x96f1 0x96f1 0x96f1
							  0x96f9 0x96f9 0x96f9 0x9702 0x9702 0x9702 0x970b 0x970b 0x970b
							  0x9714 0x9714 0x9714 0x971d 0x971d 0x971d 0x9726 0x9726 0x9726
							  0x972e 0x972e 0x972e 0x9737 0x9737 0x9737 0x9740 0x9740 0x9740
							  0x9749 0x9749 0x9749 0x9752 0x9752 0x9752 0x975b 0x975b 0x975b
							  0x9763 0x9763 0x9763 0x976c 0x976c 0x976c 0x9775 0x9775 0x9775
							  0x977e 0x977e 0x977e 0x9787 0x9787 0x9787 0x9790 0x9790 0x9790
							  0x9798 0x9798 0x9798 0x97a1 0x97a1 0x97a1 0x97aa 0x97aa 0x97aa
							  0x97b3 0x97b3 0x97b3 0x97bc 0x97bc 0x97bc 0x97c5 0x97c5 0x97c5
							  0x97cd 0x97cd 0x97cd 0x97d6 0x97d6 0x97d6 0x97df 0x97df 0x97df
							  0x97e8 0x97e8 0x97e8 0x97f1 0x97f1 0x97f1 0x97fa 0x97fa 0x97fa
							  0x9802 0x9802 0x9802 0x980b 0x980b 0x980b 0x9814 0x9814 0x9814
							  0x981d 0x981d 0x981d 0x9826 0x9826 0x9826 0x982f 0x982f 0x982f
							  0x9837 0x9837 0x9837 0x983f 0x983f 0x983f 0x9847 0x9847 0x9847
							  0x984f 0x984f 0x984f 0x9857 0x9857 0x9857 0x985f 0x985f 0x985f
							  0x9867 0x9867 0x9867 0x986e 0x986e 0x986e 0x9876 0x9876 0x9876
							  0x987e 0x987e 0x987e 0x9886 0x9886 0x9886 0x988e 0x988e 0x988e
							  0x9896 0x9896 0x9896 0x989e 0x989e 0x989e 0x98a5 0x98a5 0x98a5
							  0x98ad 0x98ad 0x98ad 0x98b5 0x98b5 0x98b5 0x98bd 0x98bd 0x98bd
							  0x98c5 0x98c5 0x98c5 0x98cd 0x98cd 0x98cd 0x98d5 0x98d5 0x98d5
							  0x98dc 0x98dc 0x98dc 0x98e4 0x98e4 0x98e4 0x98ec 0x98ec 0x98ec
							  0x98f4 0x98f4 0x98f4 0x98fc 0x98fc 0x98fc 0x9904 0x9904 0x9904
							  0x990c 0x990c 0x990c 0x9913 0x9913 0x9913 0x991b 0x991b 0x991b
							  0x9923 0x9923 0x9923 0x992b 0x992b 0x992b 0x9933 0x9933 0x9933
							  0x993b 0x993b 0x993b 0x9943 0x9943 0x9943 0x994a 0x994a 0x994a
							  0x9952 0x9952 0x9952 0x995a 0x995a 0x995a 0x9962 0x9962 0x9962
							  0x996a 0x996a 0x996a 0x9972 0x9972 0x9972 0x997a 0x997a 0x997a
							  0x9981 0x9981 0x9981 0x9989 0x9989 0x9989 0x9991 0x9991 0x9991
							  0x9999 0x9999 0x9999 0x99a1 0x99a1 0x99a1 0x99a9 0x99a9 0x99a9
							  0x99b1 0x99b1 0x99b1 0x99b8 0x99b8 0x99b8 0x99c0 0x99c0 0x99c0
							  0x99c8 0x99c8 0x99c8 0x99d0 0x99d0 0x99d0 0x99d8 0x99d8 0x99d8
							  0x99e0 0x99e0 0x99e0 0x99e8 0x99e8 0x99e8 0x99ef 0x99ef 0x99ef
							  0x99f7 0x99f7 0x99f7 0x99ff 0x99ff 0x99ff 0x9a07 0x9a07 0x9a07
							  0x9a0f 0x9a0f 0x9a0f 0x9a17 0x9a17 0x9a17 0x9a1f 0x9a1f 0x9a1f
							  0x9a26 0x9a26 0x9a26 0x9a2e 0x9a2e 0x9a2e 0x9a36 0x9a36 0x9a36
							  0x9a3e 0x9a3e 0x9a3e 0x9a46 0x9a46 0x9a46 0x9a4e 0x9a4e 0x9a4e
							  0x9a56 0x9a56 0x9a56 0x9a5d 0x9a5d 0x9a5d 0x9a65 0x9a65 0x9a65
							  0x9a6d 0x9a6d 0x9a6d 0x9a75 0x9a75 0x9a75 0x9a7d 0x9a7d 0x9a7d
							  0x9a85 0x9a85 0x9a85 0x9a8d 0x9a8d 0x9a8d 0x9a94 0x9a94 0x9a94
							  0x9a9c 0x9a9c 0x9a9c 0x9aa4 0x9aa4 0x9aa4 0x9aac 0x9aac 0x9aac
							  0x9ab4 0x9ab4 0x9ab4 0x9abc 0x9abc 0x9abc 0x9ac4 0x9ac4 0x9ac4
							  0x9acb 0x9acb 0x9acb 0x9ad3 0x9ad3 0x9ad3 0x9adb 0x9adb 0x9adb
							  0x9ae3 0x9ae3 0x9ae3 0x9aeb 0x9aeb 0x9aeb 0x9af3 0x9af3 0x9af3
							  0x9afb 0x9afb 0x9afb 0x9b02 0x9b02 0x9b02 0x9b0a 0x9b0a 0x9b0a
							  0x9b12 0x9b12 0x9b12 0x9b1a 0x9b1a 0x9b1a 0x9b22 0x9b22 0x9b22
							  0x9b2a 0x9b2a 0x9b2a 0x9b32 0x9b32 0x9b32 0x9b39 0x9b39 0x9b39
							  0x9b41 0x9b41 0x9b41 0x9b49 0x9b49 0x9b49 0x9b51 0x9b51 0x9b51
							  0x9b59 0x9b59 0x9b59 0x9b61 0x9b61 0x9b61 0x9b69 0x9b69 0x9b69
							  0x9b70 0x9b70 0x9b70 0x9b78 0x9b78 0x9b78 0x9b80 0x9b80 0x9b80
							  0x9b88 0x9b88 0x9b88 0x9b90 0x9b90 0x9b90 0x9b98 0x9b98 0x9b98
							  0x9ba0 0x9ba0 0x9ba0 0x9ba7 0x9ba7 0x9ba7 0x9baf 0x9baf 0x9baf
							  0x9bb7 0x9bb7 0x9bb7 0x9bbf 0x9bbf 0x9bbf 0x9bc7 0x9bc7 0x9bc7
							  0x9bcf 0x9bcf 0x9bcf 0x9bd7 0x9bd7 0x9bd7 0x9bde 0x9bde 0x9bde
							  0x9be6 0x9be6 0x9be6 0x9bee 0x9bee 0x9bee 0x9bf6 0x9bf6 0x9bf6
							  0x9bfe 0x9bfe 0x9bfe 0x9c06 0x9c06 0x9c06 0x9c0e 0x9c0e 0x9c0e
							  0x9c15 0x9c15 0x9c15 0x9c1d 0x9c1d 0x9c1d 0x9c25 0x9c25 0x9c25
							  0x9c2d 0x9c2d 0x9c2d 0x9c35 0x9c35 0x9c35 0x9c3d 0x9c3d 0x9c3d
							  0x9c44 0x9c44 0x9c44 0x9c4b 0x9c4b 0x9c4b 0x9c53 0x9c53 0x9c53
							  0x9c5a 0x9c5a 0x9c5a 0x9c61 0x9c61 0x9c61 0x9c69 0x9c69 0x9c69
							  0x9c70 0x9c70 0x9c70 0x9c77 0x9c77 0x9c77 0x9c7f 0x9c7f 0x9c7f
							  0x9c86 0x9c86 0x9c86 0x9c8d 0x9c8d 0x9c8d 0x9c95 0x9c95 0x9c95
							  0x9c9c 0x9c9c 0x9c9c 0x9ca3 0x9ca3 0x9ca3 0x9cab 0x9cab 0x9cab
							  0x9cb2 0x9cb2 0x9cb2 0x9cb9 0x9cb9 0x9cb9 0x9cc1 0x9cc1 0x9cc1
							  0x9cc8 0x9cc8 0x9cc8 0x9ccf 0x9ccf 0x9ccf 0x9cd7 0x9cd7 0x9cd7
							  0x9cde 0x9cde 0x9cde 0x9ce5 0x9ce5 0x9ce5 0x9ced 0x9ced 0x9ced
							  0x9cf4 0x9cf4 0x9cf4 0x9cfb 0x9cfb 0x9cfb 0x9d03 0x9d03 0x9d03
							  0x9d0a 0x9d0a 0x9d0a 0x9d12 0x9d12 0x9d12 0x9d19 0x9d19 0x9d19
							  0x9d20 0x9d20 0x9d20 0x9d28 0x9d28 0x9d28 0x9d2f 0x9d2f 0x9d2f
							  0x9d36 0x9d36 0x9d36 0x9d3e 0x9d3e 0x9d3e 0x9d45 0x9d45 0x9d45
							  0x9d4c 0x9d4c 0x9d4c 0x9d54 0x9d54 0x9d54 0x9d5b 0x9d5b 0x9d5b
							  0x9d62 0x9d62 0x9d62 0x9d6a 0x9d6a 0x9d6a 0x9d71 0x9d71 0x9d71
							  0x9d78 0x9d78 0x9d78 0x9d80 0x9d80 0x9d80 0x9d87 0x9d87 0x9d87
							  0x9d8e 0x9d8e 0x9d8e 0x9d96 0x9d96 0x9d96 0x9d9d 0x9d9d 0x9d9d
							  0x9da4 0x9da4 0x9da4 0x9dac 0x9dac 0x9dac 0x9db3 0x9db3 0x9db3
							  0x9dba 0x9dba 0x9dba 0x9dc2 0x9dc2 0x9dc2 0x9dc9 0x9dc9 0x9dc9
							  0x9dd0 0x9dd0 0x9dd0 0x9dd8 0x9dd8 0x9dd8 0x9ddf 0x9ddf 0x9ddf
							  0x9de6 0x9de6 0x9de6 0x9dee 0x9dee 0x9dee 0x9df5 0x9df5 0x9df5
							  0x9dfc 0x9dfc 0x9dfc 0x9e04 0x9e04 0x9e04 0x9e0b 0x9e0b 0x9e0b
							  0x9e13 0x9e13 0x9e13 0x9e1a 0x9e1a 0x9e1a 0x9e21 0x9e21 0x9e21
							  0x9e29 0x9e29 0x9e29 0x9e30 0x9e30 0x9e30 0x9e37 0x9e37 0x9e37
							  0x9e3f 0x9e3f 0x9e3f 0x9e46 0x9e46 0x9e46 0x9e4d 0x9e4d 0x9e4d
							  0x9e55 0x9e55 0x9e55 0x9e5c 0x9e5c 0x9e5c 0x9e63 0x9e63 0x9e63
							  0x9e6b 0x9e6b 0x9e6b 0x9e72 0x9e72 0x9e72 0x9e79 0x9e79 0x9e79
							  0x9e81 0x9e81 0x9e81 0x9e88 0x9e88 0x9e88 0x9e8f 0x9e8f 0x9e8f
							  0x9e97 0x9e97 0x9e97 0x9e9e 0x9e9e 0x9e9e 0x9ea5 0x9ea5 0x9ea5
							  0x9ead 0x9ead 0x9ead 0x9eb4 0x9eb4 0x9eb4 0x9ebb 0x9ebb 0x9ebb
							  0x9ec3 0x9ec3 0x9ec3 0x9eca 0x9eca 0x9eca 0x9ed1 0x9ed1 0x9ed1
							  0x9ed9 0x9ed9 0x9ed9 0x9ee0 0x9ee0 0x9ee0 0x9ee7 0x9ee7 0x9ee7
							  0x9eef 0x9eef 0x9eef 0x9ef6 0x9ef6 0x9ef6 0x9efd 0x9efd 0x9efd
							  0x9f05 0x9f05 0x9f05 0x9f0c 0x9f0c 0x9f0c 0x9f14 0x9f14 0x9f14
							  0x9f1b 0x9f1b 0x9f1b 0x9f22 0x9f22 0x9f22 0x9f2a 0x9f2a 0x9f2a
							  0x9f31 0x9f31 0x9f31 0x9f38 0x9f38 0x9f38 0x9f40 0x9f40 0x9f40
							  0x9f47 0x9f47 0x9f47 0x9f4e 0x9f4e 0x9f4e 0x9f56 0x9f56 0x9f56
							  0x9f5d 0x9f5d 0x9f5d 0x9f64 0x9f64 0x9f64 0x9f6c 0x9f6c 0x9f6c
							  0x9f73 0x9f73 0x9f73 0x9f7a 0x9f7a 0x9f7a 0x9f82 0x9f82 0x9f82
							  0x9f89 0x9f89 0x9f89 0x9f90 0x9f90 0x9f90 0x9f98 0x9f98 0x9f98
							  0x9f9f 0x9f9f 0x9f9f 0x9fa6 0x9fa6 0x9fa6 0x9fae 0x9fae 0x9fae
							  0x9fb5 0x9fb5 0x9fb5 0x9fbc 0x9fbc 0x9fbc 0x9fc4 0x9fc4 0x9fc4
							  0x9fcb 0x9fcb 0x9fcb 0x9fd2 0x9fd2 0x9fd2 0x9fda 0x9fda 0x9fda
							  0x9fe1 0x9fe1 0x9fe1 0x9fe8 0x9fe8 0x9fe8 0x9ff0 0x9ff0 0x9ff0
							  0x9ff7 0x9ff7 0x9ff7 0x9fff 0x9fff 0x9fff>;
				};
			};
		};
	};
	backlight {
		panel-a-edp-1080p-14-0-bl {
			status = "okay";
			compatible = "a-edp,1080p-14-0-bl";
			max-brightness = <255>;
			default-brightness = <224>;
			bl-measured = < 0 0 1 2 3 4 5 6
					7 8 9 9 10 11 12 13
					13 14 15 16 17 17 18 19
					20 21 22 22 23 24 25 26
					27 27 28 29 30 31 32 32
					33 34 35 36 37 37 38 39
					40 41 42 42 43 44 45 46
					47 48 48 49 50 51 52 53
					54 55 56 57 57 58 59 60
					61 62 63 64 65 66 67 68
					69 70 71 71 72 73 74 75
					76 77 77 78 79 80 81 82
					83 84 85 87 88 89 90 91
					92 93 94 95 96 97 98 99
					100 101 102 103 104 105 106 107
					108 109 110 111 112 113 115 116
					117 118 119 120 121 122 123 124
					125 126 127 128 129 130 131 132
					133 134 135 136 137 138 139 141
					142 143 144 146 147 148 149 151
					152 153 154 155 156 157 158 158
					159 160 161 162 163 165 166 167
					168 169 170 171 172 173 174 176
					177 178 179 180 182 183 184 185
					186 187 188 189 190 191 192 194
					195 196 197 198 199 200 201 202
					203 204 205 206 207 208 209 210
					211 212 213 214 215 216 217 219
					220 221 222 224 225 226 227 229
					230 231 232 233 234 235 236 238
					239 240 241 242 243 244 245 246
					247 248 249 250 251 252 253 255 >;
		};
	};
};
